# S6E2D3xG register map
Vendor: Cypress; File version: 2.1
CPU: CM4 r0p1, little endian, MPU, FPU, 4 interrupt priority bits
Registers are 32-bit, read-write, reset 0x0 unless marked. A register's access mark holds for its fields unless they carry their own. Offsets are from the block's base; [hi:lo] are bit positions; {n}, {i} and the like mark numbered series; 'fields as' and 'values as' point back to an identical list.

## DMAC — DMAC Registers
Base 0x40060000
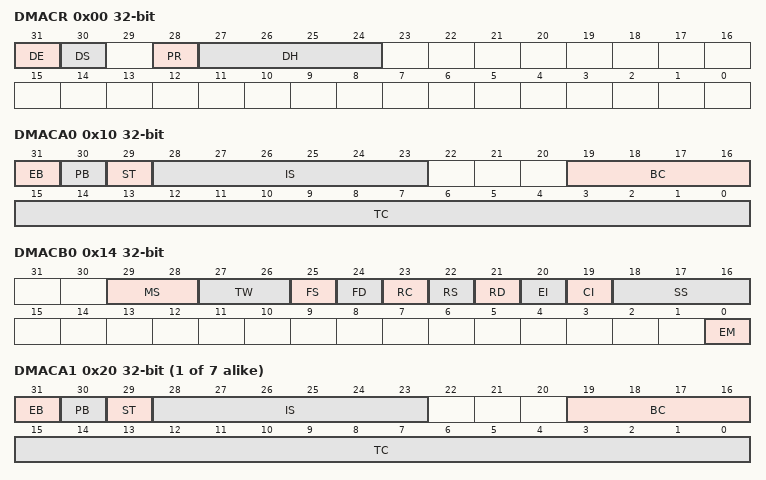
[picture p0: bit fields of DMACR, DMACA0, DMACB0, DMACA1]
0x00 DMACR — Entire DMAC Configuration Register [BHW]
  [31] DE — DMA Enable (all-channel operation enable bit)
  [30] DS — DMA Stop
  [28] PR — Priority Rotation
  [27:24] DH — DMA Halt (All-channel pause bit)
0x10 DMACA0 — Configuration A Register [BHW]
  [31] EB — Enable bit (individual-channel operation enable bit)
  [30] PB — Pause bit (individual-channel pause bit)
  [29] ST — Software Trigger
  [28:23] IS — Input Select
  [19:16] BC — Block Count
  [15:0] TC — Transfer Count
0x14 DMACB0 — Configuration B Register [BHW]
  [29:28] MS — Mode Select
  [27:26] TW — Transfer Width
  [25] FS — Fixed Source
  [24] FD — Fixed Destination
  [23] RC — Reload Count (BC/TC reload)
  [22] RS — Reload Source
  [21] RD — Reload Destination
  [20] EI — Error Interrupt (unsuccessful transfer completion interrupt enable)
  [19] CI — Completion Interrupt (successful transfer completion interrupt enable)
  [18:16] SS — Stop Status (stop status notification)
  [0] EM — Enable bit Mask (EB bit clear mask)
{0x18+0x10*i} DMACSA{i} (i=0..7) — Transfer Source Address Register {i} [BHW]
{0x1C+0x10*i} DMACDA{i} (i=0..7) — Transfer Destination Address Register {i} [BHW]
{0x10+0x10*i} DMACA{i} (i=1..7) — Configuration A Register {i} [BHW]
  fields as DMACA0
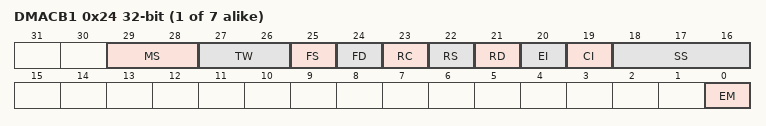
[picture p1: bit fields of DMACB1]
{0x14+0x10*i} DMACB{i} (i=1..7) — Configuration B Register {i} [BHW]
  fields as DMACB0

## DSTC — DSTC registers
Base 0x40061000
0x00 DESTP — Descriptor top address Register [BHW]
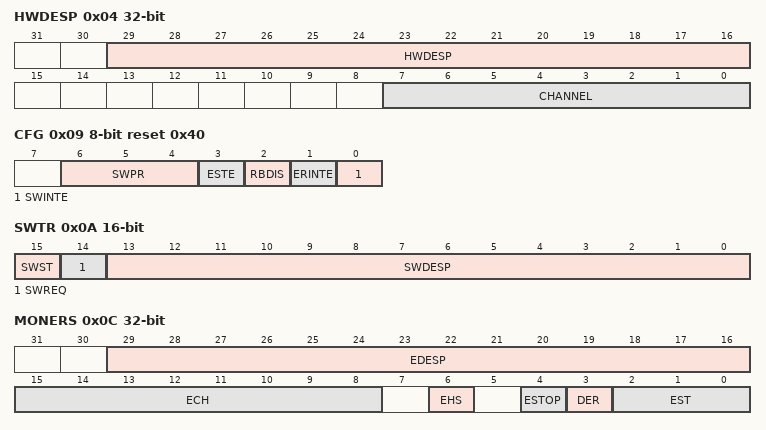
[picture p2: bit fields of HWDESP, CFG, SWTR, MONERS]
0x04 HWDESP — Hardware DES pointer Register [BHW]
  [29:16] HWDESP, [7:0] CHANNEL
0x08 CMD 8-bit reset 0x1 — Command Register [B]
0x09 CFG 8-bit reset 0x40 — Configuration Register [B]
  [6:4] SWPR — Software transfer priority
  [3] ESTE — Error stop enable
  [2] RBDIS — Read skip buffer disable
  [1] ERINTE — Error interrupt enable
  [0] SWINTE — Software interrupt enable
0x0A SWTR 16-bit — Software trigger Register [H]
  [15] SWST ro — Software status
  [14] SWREQ ro — Software request
  [13:0] SWDESP — Software DES pointer
0x0C MONERS ro — Transfer Error Status Monitor Register [BHW]
  [29:16] EDESP — Error DES pointer
  [15:8] ECH — Error hardware channel
  [6] EHS — Error hardware software
  [4] ESTOP — Error stop
  [3] DER — Double error
  [2:0] EST — Error status
{0x10+4i} DREQENB{i} (i=0..7) — DMA request enable Register {i} [BHW]
{0x30+4i} HWINT{i} ro (i=0..7) — Hardware transfer interrupt Register {i} [BHW]
{0x50+4i} HWINTCLR{i} wo (i=0..7) — Hardware transfer interrupt clear Register {i} [BHW]
{0x70+4i} DQMSK{i} ro (i=0..7) — DMA request mask Register {i} [BHW]
{0x90+4i} DQMSKCLR{i} wo (i=0..7) — DMA request mask clear Register {i} [BHW]

## PCRC — 0
Base 0x40080000
0x00 PCRC_POLY reset 0x4C11DB7 — CRC Computing Generator Polynomial Register [BHW]
0x04 PCRC_SEED reset 0xFFFFFFFF — CRC Computing Initial Value Register [BHW]
0x08 PCRC_FXOR reset 0xFFFFFFFF — CRC Computing Resault XOR Value Register [BHW]
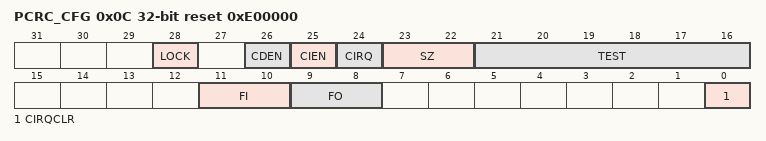
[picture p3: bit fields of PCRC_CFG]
0x0C PCRC_CFG reset 0xE00000 — CRC Computing Configuration Register [BHW]
  [28] LOCK ro
  [26] CDEN — DMA request enable
  [25] CIEN — Interrupt request enable
  [24] CIRQ ro — Interrupt request
  [23:22] SZ — Input data size
  [21:16] TEST
  [11:10] FI — Input data format
  [9:8] FO — output data format
  [0] CIRQCLR wo — Interrupt request clear
0x10 PCRC_WR — CRC Computing Input Data Register [BHW]
0x14 PCRC_RD — CRC Computing Output Data Register [BHW]

## HYPERBUS — HyperBus Interface
Base 0xD0A05000
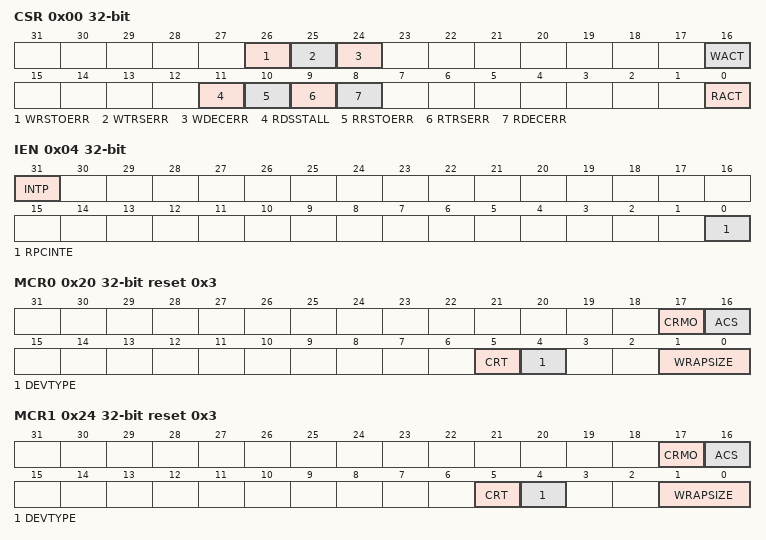
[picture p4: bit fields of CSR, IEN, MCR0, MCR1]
0x00 CSR ro — Controller Status Register [BHW]
  [26] WRSTOERR — RSTO Error in Write Transaction
  [25] WTRSERR — Transaction Error in Write Transaction
  [24] WDECERR — Decode Error in Write Transaction
  [16] WACT — Write Transaction Active
  [11] RDSSTALL — RDS Stall Error in Read Transaction
  [10] RRSTOERR — RSTO Error in Read Transaction
  [9] RTRSERR — Transaction Error in Read Transaction
  [8] RDECERR — Decode Error in Read Transaction
  [0] RACT — Read Transaction Active
0x04 IEN — Interrupt Enable Register [BHW]
  [31] INTP — Interrupt Polarity
  [0] RPCINTE — HyperBus Memory Interrupt Enable
0x08 ISR ro — Interrupt Status Register [BHW]
  [0] RPCINTS — HyperBus Memory Interrupt Status
0x10 MBR0 — Memory Base Address Register 0 [BHW]
  [31:0] MBR — Base address for memory space 0
0x14 MBR1 — Memory Base Address Register 1 [BHW]
  [31:0] MBR — Base address for memory space 0
0x20 MCR0 reset 0x3 — Memory Configuration Register 0 [BHW]
  [17] CRMO — Continuous Read Merging Option
  [16] ACS — Asymmetry Cache System Support
  [5] CRT — Configuration Register Target
  [4] DEVTYPE — Device Type
  [1:0] WRAPSIZE — Wrapped Burst Size
0x24 MCR1 reset 0x3 — Memory Configuration Register 1 [BHW]
  fields as MCR0
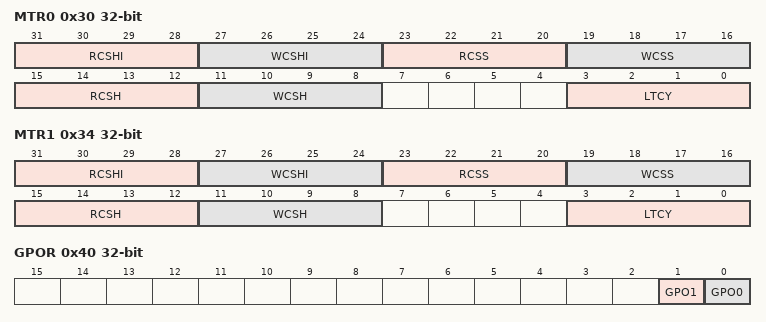
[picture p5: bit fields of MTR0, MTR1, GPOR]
0x30 MTR0 — Memory Timing Register 0 [BHW]
  [31:28] RCSHI — Read Chip Select High Between Operations
  [27:24] WCSHI — Write Chip Select High Between Operations
  [23:20] RCSS — Read Chip Select Setup To Next CK Rising Edge
  [19:16] WCSS — Write Chip Select Setup To Next CK Rising Edge
  [15:12] RCSH — Read Chip Select Hold After CK falling Edge
  [11:8] WCSH — Write Chip Select Hold After CK falling Edge
  [3:0] LTCY — Latency Cycle for HyperRAM mode
0x34 MTR1 — Memory Timing Register 1 [BHW]
  fields as MTR0
0x40 GPOR — General Purpose Output Register [BHW]
  [1] GPO1 — General Purpose Output Interface
  [0] GPO0 — General Purpose Output Interface
0x44 WPR — Write Protection Register [BHW]
  [0] WP — Write Protection
0x48 TEST — Test Register [BHW]
  [0] RVD — Reserved bit

## Notices in the file
Copyright (C) 2013-2016, Cypress Semiconductor Corporation or a
subsidiary of Cypress Semiconductor Corporation.  All rights reserved.
This software, including source code, documentation and related
materials ("Software"), is owned by Cypress Semiconductor Corporation or
one of its subsidiaries ("Cypress") and is protected by and subject to
worldwide patent protection (United States and foreign), United States
copyright laws and international treaty provisions. Therefore, you may use
this Software only as provided in the license agreement accompanying the
software package from which you obtained this Software ("EULA").
If no EULA applies, Cypress hereby grants you a personal, non-exclusive,
non-transferable license to copy, modify, and compile the
Software source code solely for use in connection with Cypress's
integrated circuit products.  Any reproduction, modification, translation,
compilation, or representation of this Software except as specified
above is prohibited without the express written permission of Cypress.
Disclaimer: THIS SOFTWARE IS PROVIDED AS-IS, WITH NO
WARRANTY OF ANY KIND, EXPRESS OR IMPLIED, INCLUDING,
BUT NOT LIMITED TO, NONINFRINGEMENT, IMPLIED
WARRANTIES OF MERCHANTABILITY AND FITNESS FOR A
PARTICULAR PURPOSE. Cypress reserves the right to make
changes to the Software without notice. Cypress does not assume any
liability arising out of the application or use of the Software or any
product or circuit described in the Software. Cypress does not
authorize its products for use in any products where a malfunction or
failure of the Cypress product may reasonably be expected to result in
significant property damage, injury or death ("High Risk Product"). By
including Cypress's product in a High Risk Product, the manufacturer
of such system or application assumes all risk of such use and in doing
so agrees to indemnify Cypress against all liability.
